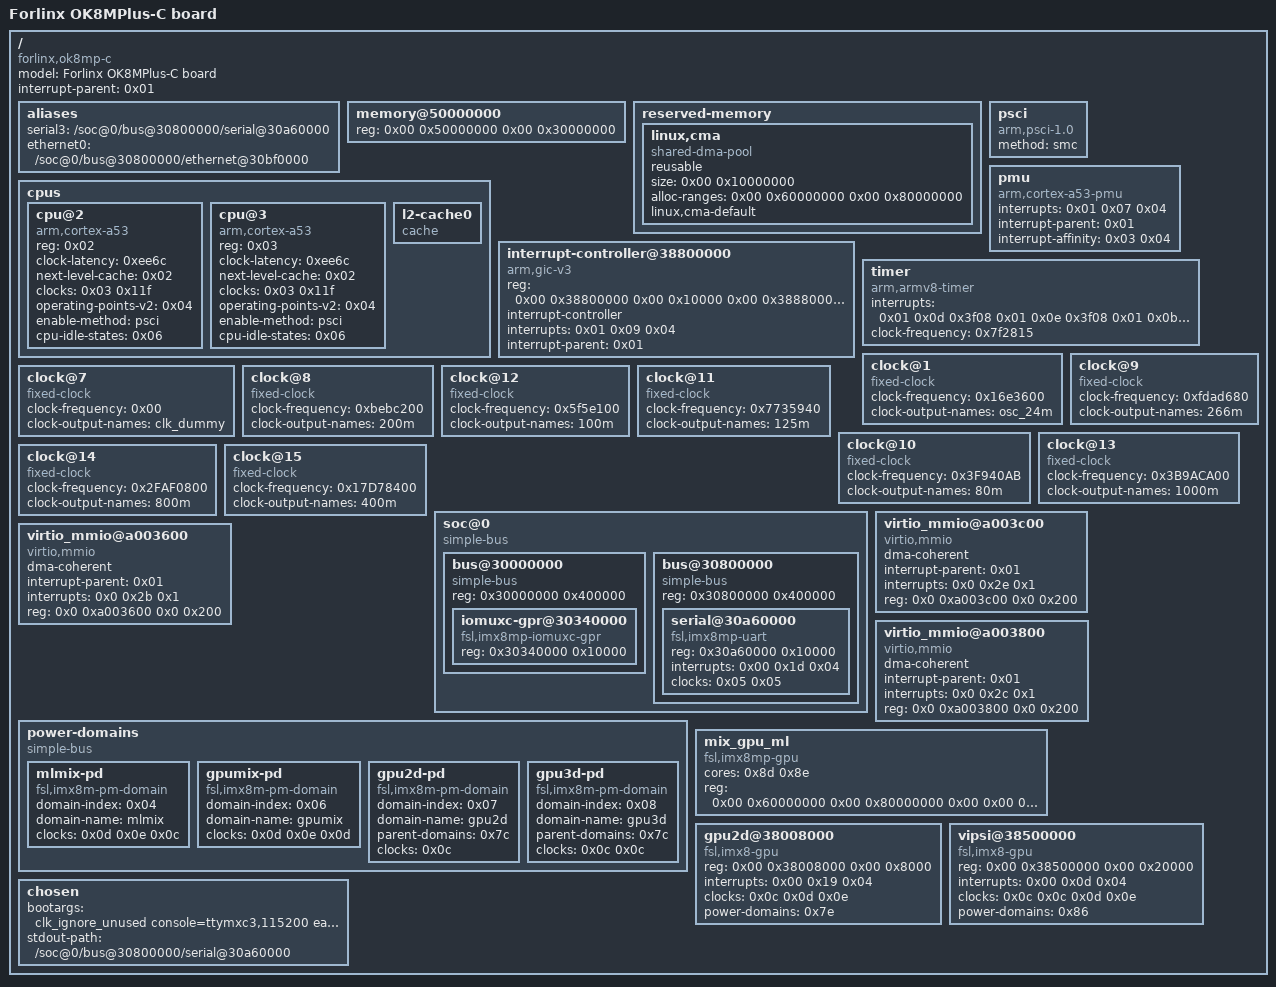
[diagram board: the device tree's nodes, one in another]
/dts-v1/;

/ {
	compatible = "forlinx,ok8mp-c\0fsl,imx8mp-evk\0fsl,/home/lgw/Documents/xwechat_files/wxid_ugo1mwfw18zq12_d8dd/msg/file/2024-07/linux2.json";
	model = "Forlinx OK8MPlus-C board";
	interrupt-parent = <0x01>;
	#address-cells = <0x02>;
	#size-cells = <0x02>;

	aliases {
		// serial1 = "/soc@0/bus@30800000/serial@30890000";
		serial3 = "/soc@0/bus@30800000/serial@30a60000";
	    // mmc3 = "/soc@0/bus@30800000/mmc@30b60000";
		ethernet0 = "/soc@0/bus@30800000/ethernet@30bf0000";
	};

	memory@50000000 {
		device_type = "memory";
		reg = <0x00 0x50000000 0x00 0x30000000>;
	};

	reserved-memory {
		#address-cells = <0x02>;
		#size-cells = <0x02>;
		ranges;

		linux,cma {
			compatible = "shared-dma-pool";
			reusable;
			size = <0x00 0x10000000>;
			alloc-ranges = <0x00 0x60000000 0x00 0x80000000>;
			linux,cma-default;
		};
	};

	cpus {
		#address-cells = <0x01>;
		#size-cells = <0x00>;
		// TODO: 增加idle-states for cpu
		// idle-states {
		// 	entry-method = "psci";

		// 	cpu-pd-wait {
		// 		// compatible = "arm,idle-state";
		// 		arm,psci-suspend-param = <0x10033>;
		// 		local-timer-stop;
		// 		entry-latency-us = <0x3e8>;
		// 		exit-latency-us = <0x2bc>;
		// 		min-residency-us = <0xa8c>;
		// 		wakeup-latency-us = <0x5dc>;
		// 		phandle = <0x06>;
		// 	};
		// };

		cpu@2 {
			device_type = "cpu";
			compatible = "arm,cortex-a53";
			reg = <0x02>;
			clock-latency = <0xee6c>;
			next-level-cache = <0x02>;
			clocks = <0x03 0x11f>;
			operating-points-v2 = <0x04>;
			enable-method = "psci";
			#cooling-cells = <0x02>;
			cpu-idle-states = <0x06>;
			phandle = <0x13>;
		};

		cpu@3 {
			device_type = "cpu";
			compatible = "arm,cortex-a53";
			reg = <0x03>;
			clock-latency = <0xee6c>;
			next-level-cache = <0x02>;
			clocks = <0x03 0x11f>;
			operating-points-v2 = <0x04>;
			enable-method = "psci";
			#cooling-cells = <0x02>;
			cpu-idle-states = <0x06>;
			phandle = <0x14>;
		};

		l2-cache0 {
			compatible = "cache";
			phandle = <0x02>;
		};
	};

	psci {
		compatible = "arm,psci-1.0";
		method = "smc";
	};

	pmu {
		compatible = "arm,cortex-a53-pmu";
		interrupts = <0x01 0x07 0x04>;
		interrupt-parent = <0x01>;
		interrupt-affinity = <0x03 0x04>;
	};

	interrupt-controller@38800000 {
		compatible = "arm,gic-v3";
		reg = <0x00 0x38800000 0x00 0x10000 0x00 0x38880000 0x00 0xc0000>;
		#interrupt-cells = <0x03>;
		interrupt-controller;
		interrupts = <0x01 0x09 0x04>;
		interrupt-parent = <0x01>;
		phandle = <0x01>;
	};

	timer {
		compatible = "arm,armv8-timer";
		interrupts = <0x01 0x0d 0x3f08 0x01 0x0e 0x3f08 0x01 0x0b 0x3f08 0x01 0x0a 0x3f08>;
		clock-frequency = <0x7f2815>;
	};

	clock@1 {
		compatible = "fixed-clock";
		#clock-cells = <0x00>;
		clock-frequency = <0x16e3600>;
		clock-output-names = "osc_24m";
		phandle = <0x05>;
	};


	clock@7 {
		compatible = "fixed-clock";
		#clock-cells = <0x00>;
		clock-frequency = <0x00>;
		clock-output-names = "clk_dummy";
		phandle = <0x06>;
	};

	clock@9 {
		compatible = "fixed-clock";
		#clock-cells = <0x00>;
		clock-frequency = <0xfdad680>;
		clock-output-names = "266m";
		phandle = <0x07>;
	};
	
	clock@8 {
		compatible = "fixed-clock";
		#clock-cells = <0x00>;
		clock-frequency = <0xbebc200>;
		clock-output-names = "200m";
		phandle = <0x08>;
	};

	clock@12 {
		compatible = "fixed-clock";
		#clock-cells = <0x00>;
		clock-frequency = <0x5f5e100>;
		clock-output-names = "100m";
		phandle = <0x09>;
	};

	clock@11 {
		compatible = "fixed-clock";
		#clock-cells = <0x00>;
		clock-frequency = <0x7735940>;
		clock-output-names = "125m";
		phandle = <0x0a>;
	};

	clock@10 {
		compatible = "fixed-clock";
		#clock-cells = <0x00>;
		clock-frequency = <0x3F940AB>;
		clock-output-names = "80m";
		phandle = <0x0b>;
	};

	clock@13 {
		compatible = "fixed-clock";
		#clock-cells = <0x00>;
		clock-frequency = <0x3B9ACA00>;
		clock-output-names = "1000m";
		phandle = <0x0c>;
	};
	
	clock@14 {
		compatible = "fixed-clock";
		#clock-cells = <0x00>;
		clock-frequency = <0x2FAF0800>;
		clock-output-names = "800m";
		phandle = <0x0d>;
	};

	clock@15 {
		compatible = "fixed-clock";
		#clock-cells = <0x00>;
		clock-frequency = <0x17D78400>;
		clock-output-names = "400m";
		phandle = <0x0e>;
	};



	soc@0 {
		compatible = "simple-bus";
		#address-cells = <0x01>;
		#size-cells = <0x01>;
		ranges = <0x00 0x00 0x00 0x3e000000>;
		// dma-ranges = <0x40000000 0x00 0x40000000 0xc0000000>;

		bus@30000000 {
			compatible = "simple-bus";
			reg = <0x30000000 0x400000>;
			#address-cells = <0x01>;
			#size-cells = <0x01>;
			ranges;
			
			iomuxc-gpr@30340000 {
			 	compatible = "fsl,imx8mp-iomuxc-gpr\0fsl,imx7d-iomuxc-gpr\0fsl,imx6q-iomuxc-gpr\0syscon";
			 	reg = <0x30340000 0x10000>;
			 	phandle = <0x29>;
			};
		};

		bus@30800000 {
			compatible = "simple-bus";
			#address-cells = <0x01>;
			#size-cells = <0x01>;
			reg = <0x30800000 0x400000>;
			ranges;

			// serial@30890000 {
			// 	compatible = "fsl,imx8mq-uart\0fsl,imx6q-uart";
			// 	reg = <0x30890000 0x10000>;
			// 	interrupts = <0x00 0x1b 0x04>;
			// 	status = "okay";
			// 	clocks = <0x05 0x05>;
			// 	clock-names = "ipg\0per";
			// };

			serial@30a60000 {
				compatible = "fsl,imx8mp-uart\0fsl,imx6q-uart";
				reg = <0x30a60000 0x10000>;
				interrupts = <0x00 0x1d 0x04>;
				clocks = <0x05 0x05>;
				clock-names = "ipg\0per";
				status = "okay";
				// dmas = <0x22 0x1c 0x04 0x00 0x22 0x1d 0x04 0x00>;
				// dma-names = "rx\0tx";
				// status = "disabled";
			};
			// sd card
			// mmc@30b50000 {
			// 	compatible = "fsl,imx8mm-usdhc\0fsl,imx7d-usdhc";
			// 	reg = <0x30b50000 0x10000>;
			// 	interrupts = <0x00 0x17 0x04>;
			// 	clocks = <0x06 0x07 0x08>;
			// 	clock-names = "ipg\0ahb\0per";
			// 	fsl,tuning-start-tap = <0x14>;
			// 	fsl,tuning-step = <0x02>;
			// 	bus-width = <0x04>;
			// 	status = "okay";
			// };
			// emmc
			// mmc@30b60000 {
			// 	compatible = "fsl,imx8mm-usdhc\0fsl,imx7d-usdhc";
			// 	reg = <0x30b60000 0x10000>;
			// 	interrupts = <0x00 0x18 0x04>;
			// 	fsl,tuning-start-tap = <0x14>;
			// 	fsl,tuning-step = <0x02>;
			// 	status = "okay";
			// 	clocks = <0x06 0x07 0x08>;
			// 	clock-names = "ipg\0ahb\0per";
			// 	bus-width = <0x08>;
			// 	non-removable;
			// };


			// ethernet@30bf0000 {
			// 	compatible = "nxp,imx8mp-dwmac-eqos\0snps,dwmac-5.10a";
			// 	reg = <0x30bf0000 0x10000>;
			// 	interrupts = <0x00 0x86 0x04 0x00 0x87 0x04>;
			// 	interrupt-names = "eth_wake_irq\0macirq";
			// 	clocks = <0x07 0x0b 0x09 0x0a>;
			// 	clock-names = "stmmaceth\0pclk\0ptp_ref\0tx";
			// 	// assigned-clocks = <0x03 0x5e 0x03 0x82 0x03 0x81>;
			// 	// assigned-clock-parents = <0x03 0x36 0x03 0x3a 0x03 0x3b>;
			// 	// assigned-clock-rates = <0x00 0x5f5e100 0x7735940>;
			// 	// nvmem-cells = <0x52>;
			// 	// nvmem-cell-names = "mac-address";
			// 	// nvmem_macaddr_swap;
			// 	intf_mode = <0x29 0x04>;
			// 	status = "okay";
			// 	// pinctrl-names = "default";
			// 	// pinctrl-0 = <0x53>;
			// 	reset-gpio = <0x25 0x05 0x01>;
			// 	phy-mode = "rgmii-id";
			// 	phy-handle = <0x54>;

			// 	mdio {
			// 		compatible = "snps,dwmac-mdio";
			// 		#address-cells = <0x01>;
			// 		#size-cells = <0x00>;

			// 		ethernet-phy@1 {
			// 			compatible = "ethernet-phy-ieee802.3-c22";
			// 			reg = <0x01>;
			// 			eee-broken-1000t;
			// 			at803x,vddio-1p8v;
			// 			at803x,hibernate-disable;
			// 			phandle = <0x54>;
			// 		};
			// 	};
			// };
		};
	};
	// virtio blk
	virtio_mmio@a003c00 {
		dma-coherent;
		interrupt-parent = <0x01>;
		interrupts = <0x0 0x2e 0x1>;
		reg = <0x0 0xa003c00 0x0 0x200>;
		compatible = "virtio,mmio";
	};
	// virtio net
	virtio_mmio@a003600 {
		dma-coherent;
		interrupt-parent = <0x01>;
		interrupts = <0x0 0x2b 0x1>;
		reg = <0x0 0xa003600 0x0 0x200>;
		compatible = "virtio,mmio";
	};

	// virtio serial
	virtio_mmio@a003800 {
		dma-coherent;
		interrupt-parent = <0x01>;
		interrupts = <0x0 0x2c 0x1>;
		reg = <0x0 0xa003800 0x0 0x200>;
		compatible = "virtio,mmio";
	};
	
	power-domains {
		compatible = "simple-bus";

		mlmix-pd {
			compatible = "fsl,imx8m-pm-domain";
			#power-domain-cells = <0x00>;
			domain-index = <0x04>;
			domain-name = "mlmix";
			clocks = <0x0d 0x0e 0x0c>;
			phandle = <0x86>;
		};

		gpumix-pd {
			compatible = "fsl,imx8m-pm-domain";
			#power-domain-cells = <0x00>;
			domain-index = <0x06>;
			domain-name = "gpumix";
			clocks = <0x0d 0x0e 0x0d>;
			phandle = <0x7c>;
		};

		gpu2d-pd {
			compatible = "fsl,imx8m-pm-domain";
			#power-domain-cells = <0x00>;
			domain-index = <0x07>;
			domain-name = "gpu2d";
			parent-domains = <0x7c>;
			clocks = <0x0c>;
			phandle = <0x7e>;
		};

		gpu3d-pd {
			compatible = "fsl,imx8m-pm-domain";
			#power-domain-cells = <0x00>;
			domain-index = <0x08>;
			domain-name = "gpu3d";
			parent-domains = <0x7c>;
			clocks = <0x0c 0x0c>;
			phandle = <0x7d>;
		};
	};

	mix_gpu_ml {
		compatible = "fsl,imx8mp-gpu\0fsl,imx8-gpu-ss";
		cores = <0x8d 0x8e>;
		reg = <0x00 0x60000000 0x00 0x80000000 0x00 0x00 0x00 0x10000000>;
		reg-names = "phys_baseaddr\0contiguous_mem";
		status = "okay";
	};

	// gpu3d@38000000 {
	// 	compatible = "fsl,imx8-gpu";
	// 	reg = <0x00 0x38000000 0x00 0x8000>;
	// 	interrupts = <0x00 0x03 0x04>;
	// 	clocks = <0x0c 0x0c 0x0d 0x0e>;
	// 	clock-names = "core\0shader\0axi\0ahb";
	// 	// to be config:
	// 	// assigned-clocks = <0x03 0x45 0x03 0x46 0x03 0x65 0x03 0x66>;
	// 	// assigned-clock-parents = <0x03 0x41 0x03 0x41 0x03 0x38 0x03 0x38>;
	// 	// assigned-clock-rates = <0x3b9aca00 0x3b9aca00 0x2faf0800 0x17d78400>;
	// 	power-domains = <0x7d>;
	// 	status = "okay";
	// 	phandle = <0x8c>;
	// };
	
	gpu2d@38008000 {
		compatible = "fsl,imx8-gpu";
		reg = <0x00 0x38008000 0x00 0x8000>;
		interrupts = <0x00 0x19 0x04>;
		clocks = <0x0c 0x0d 0x0e>;
		clock-names = "core\0axi\0ahb";
		// assigned-clocks = <0x03 0x47 0x03 0x65 0x03 0x66>;
		// assigned-clock-parents = <0x03 0x41 0x03 0x38 0x03 0x38>;
		// assigned-clock-rates = <0x3b9aca00 0x2faf0800 0x17d78400>;
		power-domains = <0x7e>;
		status = "okay";
		phandle = <0x8e>;
	};

	vipsi@38500000 {
		compatible = "fsl,imx8-gpu\0fsl,imx8-vipsi";
		reg = <0x00 0x38500000 0x00 0x20000>;
		interrupts = <0x00 0x0d 0x04>;
		clocks = <0x0c 0x0c 0x0d 0x0e>;
		clock-names = "core\0shader\0axi\0ahb";
		// assigned-clocks = <0x03 0x44 0x03 0x69 0x03 0x6a>;
		// assigned-clock-parents = <0x03 0x41 0x03 0x38 0x03 0x38>;
		// assigned-clock-rates = <0x3b9aca00 0x2faf0800 0x17d78400>;
		power-domains = <0x86>;
		status = "okay";
		phandle = <0x8d>;
	};

	chosen {
		// real blk and real console:
		// bootargs = "clk_ignore_unused console=ttymxc3,115200 earlycon=ec_imx6q3,0x30a60000,115200 root=/dev/mmcblk3p2 rootwait rw";
		// stdout-path = "/soc@0/bus@30800000/serial@30a60000";

		// virtio blk and real console:
		bootargs = "clk_ignore_unused console=ttymxc3,115200 earlycon=ec_imx6q3,0x30a60000,115200 root=/dev/vda rootwait rw";
		stdout-path = "/soc@0/bus@30800000/serial@30a60000";

		// virtio blk and virtio console:
		// bootargs = "clk_ignore_unused earlycon=virtio,mmio,0xa003800 console=hvc0 root=/dev/vda rootwait rw";
		// stdout-path = "/virtio_mmio@a003800";
	};
};
